VERSION "1.0"

NS_ :

BS_:

BU_: BCM ESC ECM ACU RLS RKE

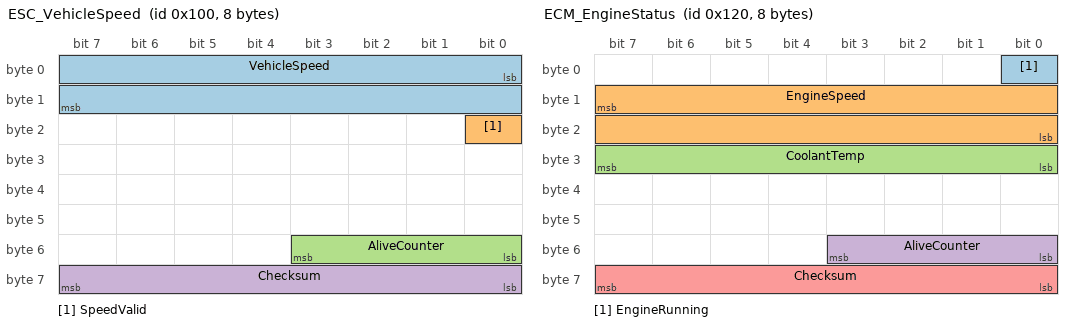
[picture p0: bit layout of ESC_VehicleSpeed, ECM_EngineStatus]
BO_ 256 ESC_VehicleSpeed: 8 ESC
 SG_ VehicleSpeed : 0|16@1+ (0.01,0) [0|655.35] "km/h" BCM
 SG_ SpeedValid : 16|1@1+ (1,0) [0|1] "" BCM
 SG_ AliveCounter : 48|4@1+ (1,0) [0|15] "" BCM
 SG_ Checksum : 56|8@1+ (1,0) [0|255] "" BCM

BO_ 288 ECM_EngineStatus: 8 ECM
 SG_ EngineRunning : 0|1@1+ (1,0) [0|1] "" BCM
 SG_ EngineSpeed : 15|16@0+ (0.25,0) [0|16383.75] "rpm" BCM
 SG_ CoolantTemp : 24|8@1- (1,0) [-40|127] "degC" BCM
 SG_ AliveCounter : 48|4@1+ (1,0) [0|15] "" BCM
 SG_ Checksum : 56|8@1+ (1,0) [0|255] "" BCM

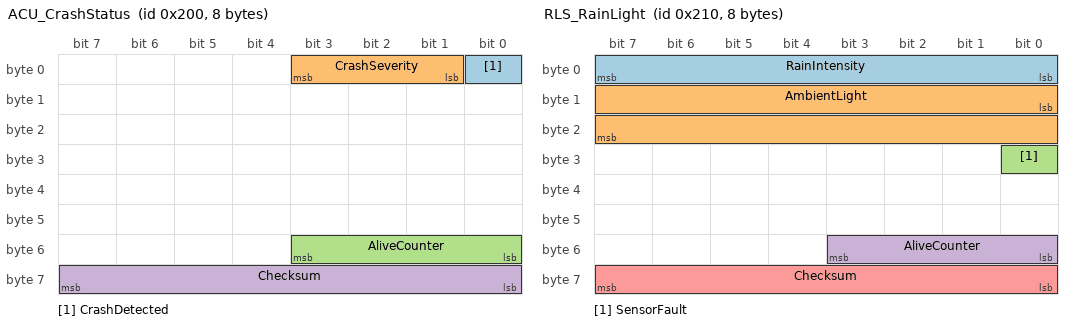
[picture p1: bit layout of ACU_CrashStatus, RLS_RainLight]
BO_ 512 ACU_CrashStatus: 8 ACU
 SG_ CrashDetected : 0|1@1+ (1,0) [0|1] "" BCM
 SG_ CrashSeverity : 1|3@1+ (1,0) [0|7] "" BCM
 SG_ AliveCounter : 48|4@1+ (1,0) [0|15] "" BCM
 SG_ Checksum : 56|8@1+ (1,0) [0|255] "" BCM

BO_ 528 RLS_RainLight: 8 RLS
 SG_ RainIntensity : 0|8@1+ (0.5,0) [0|100] "%" BCM
 SG_ AmbientLight : 8|16@1+ (1,0) [0|65535] "lux" BCM
 SG_ SensorFault : 24|1@1+ (1,0) [0|1] "" BCM
 SG_ AliveCounter : 48|4@1+ (1,0) [0|15] "" BCM
 SG_ Checksum : 56|8@1+ (1,0) [0|255] "" BCM

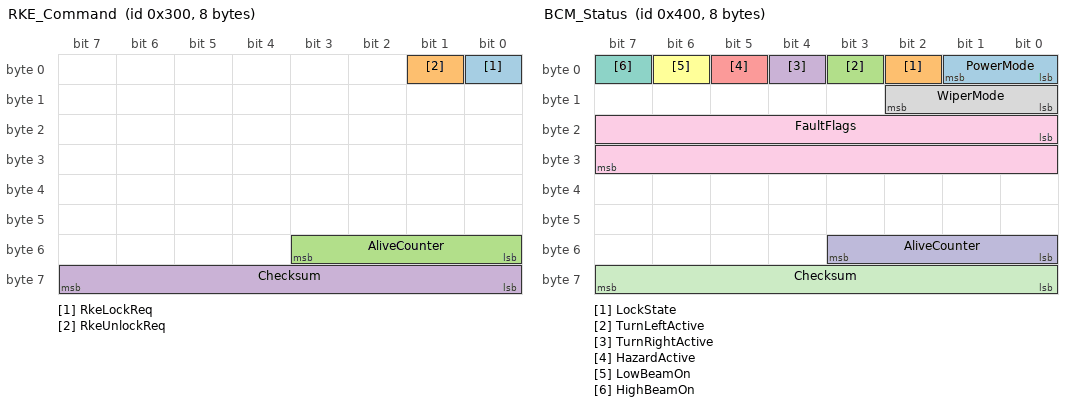
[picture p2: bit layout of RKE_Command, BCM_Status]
BO_ 768 RKE_Command: 8 RKE
 SG_ RkeLockReq : 0|1@1+ (1,0) [0|1] "" BCM
 SG_ RkeUnlockReq : 1|1@1+ (1,0) [0|1] "" BCM
 SG_ AliveCounter : 48|4@1+ (1,0) [0|15] "" BCM
 SG_ Checksum : 56|8@1+ (1,0) [0|255] "" BCM

BO_ 1024 BCM_Status: 8 BCM
 SG_ PowerMode : 0|2@1+ (1,0) [0|3] "" ESC,ECM
 SG_ LockState : 2|1@1+ (1,0) [0|1] "" ESC,ECM
 SG_ TurnLeftActive : 3|1@1+ (1,0) [0|1] "" ESC
 SG_ TurnRightActive : 4|1@1+ (1,0) [0|1] "" ESC
 SG_ HazardActive : 5|1@1+ (1,0) [0|1] "" ESC
 SG_ LowBeamOn : 6|1@1+ (1,0) [0|1] "" ESC
 SG_ HighBeamOn : 7|1@1+ (1,0) [0|1] "" ESC
 SG_ WiperMode : 8|3@1+ (1,0) [0|7] "" ESC
 SG_ FaultFlags : 16|16@1+ (1,0) [0|65535] "" ESC,ECM
 SG_ AliveCounter : 48|4@1+ (1,0) [0|15] "" ESC,ECM
 SG_ Checksum : 56|8@1+ (1,0) [0|255] "" ESC,ECM

CM_ BO_ 512 "Airbag control unit crash status. CrashDetected latches for at least 1 s.";
CM_ SG_ 1024 FaultFlags "Bit field of active BCM DTCs, see include/bcm/app/dtc.hpp";

BA_DEF_ BO_ "GenMsgCycleTime" INT 0 10000;
BA_DEF_ BO_ "RxTimeoutMs" INT 0 10000;
BA_DEF_DEF_ "GenMsgCycleTime" 0;
BA_DEF_DEF_ "RxTimeoutMs" 0;
BA_ "GenMsgCycleTime" BO_ 256 20;
BA_ "RxTimeoutMs" BO_ 256 100;
BA_ "GenMsgCycleTime" BO_ 288 100;
BA_ "RxTimeoutMs" BO_ 288 500;
BA_ "GenMsgCycleTime" BO_ 512 50;
BA_ "RxTimeoutMs" BO_ 512 250;
BA_ "GenMsgCycleTime" BO_ 528 100;
BA_ "RxTimeoutMs" BO_ 528 500;
BA_ "GenMsgCycleTime" BO_ 1024 100;

VAL_ 1024 PowerMode 0 "OFF" 1 "ACC" 2 "RUN" 3 "CRANK" ;
VAL_ 1024 WiperMode 0 "OFF" 1 "INTERMITTENT" 2 "LOW" 3 "HIGH" 4 "PARKING" 5 "STALLED" 6 "WASH" ;
